# GPIO register map
Vendor: Texas Instruments
Peripheral module from a debugger description file (folder am335x).
Registers are 32-bit, read-write, no defined reset value unless marked. A register's access mark holds for its fields unless they carry their own. Offsets are as the file gives them; lines under a group give offsets from that group; [hi:lo] are bit positions; {n}, {i} and the like mark numbered series; 'fields as' and 'values as' point back to an identical list; <NAME> marks a mode.

## GPIO
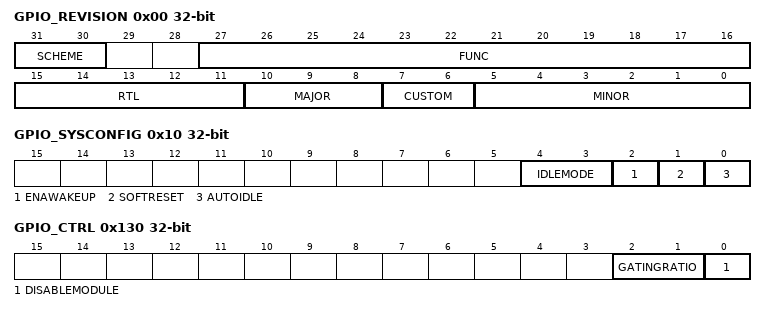
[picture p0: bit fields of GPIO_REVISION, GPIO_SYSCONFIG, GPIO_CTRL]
0x00 GPIO_REVISION ro — The GPIO revision register is a read only register containing the revision number of the GPIO module. A write to this register has no effect, the same as the reset.
  [31:30] SCHEME — Used to distinguish between old Scheme and current.
  [27:16] FUNC — Indicates a software compatible module family.
  [15:11] RTL — RTL version
  [10:8] MAJOR — Major Revision
  [7:6] CUSTOM — Indicates a special version for a particular device.
  [5:0] MINOR — Minor Revision
0x10 GPIO_SYSCONFIG access per field — The GPIO_SYSCONFIG register controls the various parameters of the L4 interconnect. When the AUTOIDLE bit is set, the GPIO_DATAIN read command has a 3 OCP cycle latency due to the data in sample gating mechanism. When the AUTOIDLE bit is not set, the GPIO_DATAIN read command has a 2 OCP cycle latency.
  [4:3] IDLEMODE rw — Power Management, Req/Ack control.
  [2] ENAWAKEUP rw
  [1] SOFTRESET rw — Software reset. This bit is automatically reset by the hardware. During reads, it always returns 0.
  [0] AUTOIDLE rw — Internal interface clock gating strategy
0x24 GPIO_IRQSTATUS_RAW_0 — The GPIO_IRQSTATUS_RAW_0 register provides core status information for the interrupt handling, showing all active events (enabled and not enabled). The fields are read-write. Writing a 1 to a bit sets it to 1, that is, triggers the IRQ (mostly for debug). Writing a 0 has no effect, that is, the register value is not be modified. Only enabled, active events trigger an actual interrupt request on the IRQ output line.
  [31:0] INTLINE_n — Interrupt n status.
0x28 GPIO_IRQSTATUS_RAW_1 — The GPIO_IRQSTATUS_RAW_1 register provides core status information for the interrupt handling, showing all active events (enabled and not enabled). The fields are read-write. Writing a 1 to a bit sets it to 1, that is, triggers the IRQ (mostly for debug). Writing a 0 has no effect, that is, the register value is not be modified. Only enabled, active events trigger an actual interrupt request on the IRQ output line.
  [31:0] INTLINE_n — Interrupt n status.
0x2C GPIO_IRQSTATUS_0 access not given — The GPIO_IRQSTATUS_0 register provides core status information for the interrupt handling, showing all active events which have been enabled. The fields are read-write. Writing a 1 to a bit clears the bit to 0, that is, clears the IRQ. Writing a 0 has no effect, that is, the register value is not modified. Only enabled, active events trigger an actual interrupt request on the IRQ output line.
  [31:0] INTLINE_n — Interrupt n status. (access R/W1C)
0x30 GPIO_IRQSTATUS_1 access not given — The GPIO_IRQSTATUS_1 register provides core status information for the interrupt handling, showing all active events which have been enabled. The fields are read-write. Writing a 1 to a bit clears the bit to 0, that is, clears the IRQ. Writing a 0 has no effect, that is, the register value is not modified. Only enabled, active events trigger an actual interrupt request on the IRQ output line.
  [31:0] INTLINE_n — Interrupt n status. (access R/W1C)
0x34 GPIO_IRQSTATUS_SET_0 — All 1-bit fields in the GPIO_IRQSTATUS_SET_0 register enable a specific interrupt event to trigger an interrupt request. Writing a 1 to a bit enables the interrupt field. Writing a 0 has no effect, that is, the register value is not modified.
  [31:0] INTLINE_n — Interrupt n enable
0x38 GPIO_IRQSTATUS_SET_1 — All 1-bit fields in the GPIO_IRQSTATUS_SET_1 register enable a specific interrupt event to trigger an interrupt request. Writing a 1 to a bit enables the interrupt field. Writing a 0 has no effect, that is, the register value is not modified.
  [31:0] INTLINE_n — Interrupt n enable
0x3C GPIO_IRQSTATUS_CLR_0 — All 1-bit fields in the GPIO_IRQSTATUS_CLR_0 register clear a specific interrupt event. Writing a 1 to a bit disables the interrupt field. Writing a 0 has no effect, that is, the register value is not modified.
  [31:0] INTLINE_n — Interrupt n enable
0x40 GPIO_IRQSTATUS_CLR_1 — All 1-bit fields in the GPIO_IRQSTATUS_CLR_1 register clear a specific interrupt event. Writing a 1 to a bit disables the interrupt field. Writing a 0 has no effect, that is, the register value is not modified.
  [31:0] INTLINE_n — Interrupt n enable
0x44 GPIO_IRQWAKEN_0 — Per-event wakeup enable vector (corresponding to first line of interrupt). Every 1-bit field in the GPIO_IRQWAKEN_0 register enables a specific (synchronous) IRQ request source to generate an asynchronous wakeup (on the appropriate swakeup line). This register allows the user to mask the expected transition on input GPIO from generating a wakeup request. The GPIO_IRQWAKEN_0 is programmed synchronously with the interface clock before any Idle mode request coming from the host processor. Note: In Force-Idle mode, the module wake-up feature is totally inhibited. The wake-up generation can also be gated at module level using the EnaWakeUp bit from GPIO_SYSCONFIG register.
  [31:0] INTLINE — Wakeup Enable for Interrupt Line
0x48 GPIO_IRQWAKEN_1 — Per-event wakeup enable vector (corresponding to second line of interrupt). Every 1-bit field in the GPIO_IRQWAKEN_1 register enables a specific (synchronous) IRQ request source to generate an asynchronous wakeup (on the appropriate swakeup line). This register allows the user to mask the expected transition on input GPIO from generating a wakeup request. The GPIO_IRQWAKEN_1 is programmed synchronously with the interface clock before any Idle mode request coming from the host processor. Note: In Force-Idle mode, the module wake-up feature is totally inhibited. The wake-up generation can also be gated at module level using the EnaWakeUp bit from GPIO_SYSCONFIG register.
  [31:0] INTLINE — Wakeup Enable for Interrupt Line
0x114 GPIO_SYSSTATUS ro — The GPIO_SYSSTATUS register provides the reset status information about the GPIO module. It is a read-only register; a write to this register has no effect.
  [0] RESETDONE — Reset status information.
0x130 GPIO_CTRL access per field — The GPIO_CTRL register controls the clock gating functionality. The DISABLEMODULE bit controls a clock gating feature at the module level. When set, this bit forces the clock gating for all internal clock paths. Module internal activity is suspended. System interface is not affected by this bit. System interface clock gating is controlled with the AUTOIDLE bit in the system configuration register (GPIO_SYSCONFIG). This bit is to be used for power saving when the module is not used because of the multiplexing configuration selected at the chip level. This bit has precedence over all other internal configuration bits.
  [2:1] GATINGRATIO rw — Gating Ratio. Controls the clock gating for the event detection logic.
  [0] DISABLEMODULE rw — Module Disable
0x134 GPIO_OE — The GPIO_OE register is used to enable the pins output capabilities. At reset, all the GPIO related pins are configured as input and output capabilities are disabled. This register is not used within the module, its only function is to carry the pads configuration. When the application is using a pin as an output and does not want interrupt generation from this pin, the application can/has to properly configure the Interrupt Enable registers.
  [31:0] OUTPUTEN_n — Output Data Enable
0x138 GPIO_DATAIN ro — The GPIO_DATAIN register is used to register the data that is read from the GPIO pins. The GPIO_DATAIN register is a read-only register. The input data is sampled synchronously with the interface clock and then captured in the GPIO_DATAIN register synchronously with the interface clock. So, after changing, GPIO pin levels are captured into this register after two interface clock cycles (the required cycles to synchronize and to write the data). When the AUTOIDLE bit in the system configuration register (GPIO_SYSCONFIG) is set, the GPIO_DATAIN read command has a 3 OCP cycle latency due to the data in sample gating mechanism. When the AUTOIDLE bit is not set, the GPIO_DATAIN read command has a 2 OCP cycle latency.
  [31:0] DATAIN — Sampled Input Data
0x13C GPIO_DATAOUT — The GPIO_DATAOUT register is used for setting the value of the GPIO output pins. Data is written to the GPIO_DATAOUT register synchronously with the interface clock. This register can be accessed with direct read/write operations or using the alternate Set/Clear feature. This feature enables to set or clear specific bits of this register with a single write access to the set data output register (GPIO_SETDATAOUT) or to the clear data output register (GPIO_CLEARDATAOUT) address.
  [31:0] DATAOUT — Data to set on output pins
0x140 GPIO_LEVELDETECT0 — The GPIO_LEVELDETECT0 register is used to enable/disable for each input lines the low-level (0) detection to be used for the interrupt request generation. Enabling at the same time high-level detection and low-level detection for one given pin makes a constant interrupt generator.
  [31:0] LEVELDETECT0_n — Low Level Interrupt Enable
0x144 GPIO_LEVELDETECT1 — The GPIO_LEVELDETECT1 register is used to enable/disable for each input lines the high-level (1) detection to be used for the interrupt request generation. Enabling at the same time high-level detection and low-level detection for one given pin makes a constant interrupt generator.
  [31:0] LEVELDETECT1_n — High Level Interrupt Enable
0x148 GPIO_RISINGDETECT — The GPIO_RISINGDETECT register is used to enable/disable for each input lines the rising-edge (transition 0 to 1) detection to be used for the interrupt request generation.
  [31:0] RISINGDETECT_n — Rising Edge Interrupt Enable
0x14C GPIO_FALLINGDETECT — The GPIO_FALLINGDETECT register is used to enable/disable for each input lines the falling-edge (transition 1 to 0) detection to be used for the interrupt request generation.
  [31:0] FALLINGDETECT_n — Falling Edge Interrupt Enable
0x150 GPIO_DEBOUNCENABLE — The GPIO_DEBOUNCENABLE register is used to enable/disable the debouncing feature for each input line.
  [31:0] DEBOUNCEENABLE_n — Input Debounce Enable
0x154 GPIO_DEBOUNCINGTIME — The GPIO_DEBOUNCINGTIME register controls debouncing time (the value is global for all ports). The debouncing cell is running with the debouncing clock (32 kHz), this register represents the number of the clock cycle(s) (31 s long) to be used.
  [7:0] DEBOUNCETIME — Input Debouncing Value in 31 microsecond steps. Debouncing time = (DEBOUNCETIME + 1) - 31 microseconds
0x190 GPIO_CLEARDATAOUT — Writing a 1 to a bit in the GPIO_CLEARDATAOUT register clears to 0 the corresponding bit in the GPIO_DATAOUT register; writing a 0 has no effect. A read of the GPIO_CLEARDATAOUT register returns the value of the data output register (GPIO_DATAOUT).
  [31:0] INTLINE_n — Clear Data Output Register
0x194 GPIO_SETDATAOUT — Writing a 1 to a bit in the GPIO_SETDATAOUT register sets to 1 the corresponding bit in the GPIO_DATAOUT register; writing a 0 has no effect. A read of the GPIO_SETDATAOUT register returns the value of the data output register (GPIO_DATAOUT).
  [31:0] INTLINE_n — Set Data Output Register
